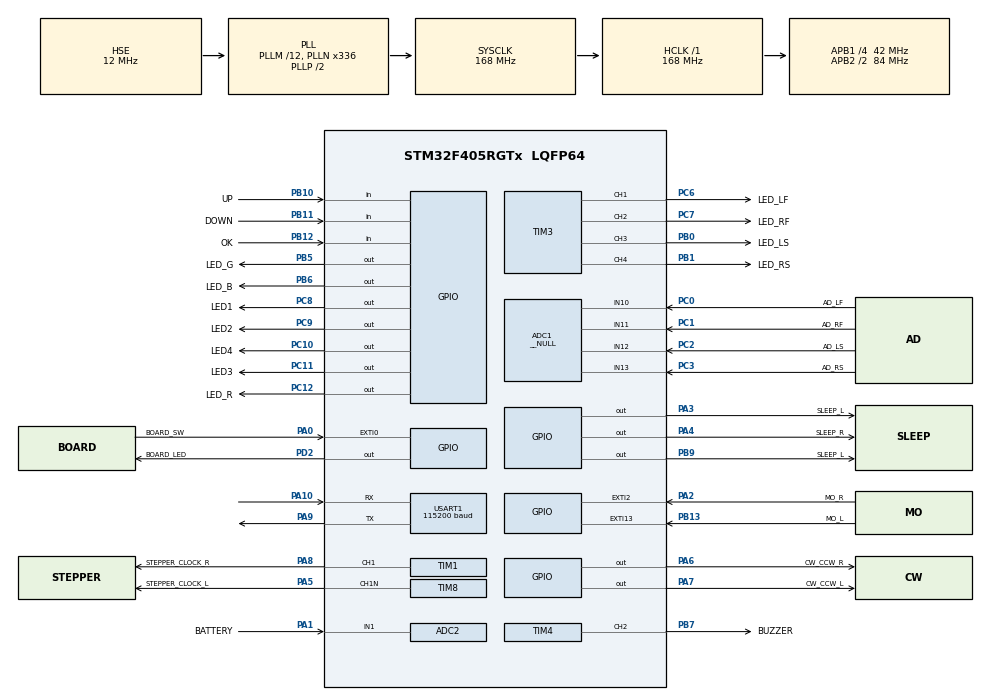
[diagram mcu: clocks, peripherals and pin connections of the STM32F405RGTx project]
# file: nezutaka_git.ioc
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ADC1.Channel-2\#ChannelRegularConversion=ADC_CHANNEL_10
ADC1.Mode=__NULL
ADC1.NbrOfConversionFlag=1
ADC1.Rank-2\#ChannelRegularConversion=1
ADC1.SamplingTime-2\#ChannelRegularConversion=ADC_SAMPLETIME_3CYCLES
ADC1.master=1
ADC2.Channel-0\#ChannelRegularConversion=ADC_CHANNEL_1
ADC2.NbrOfConversionFlag=1
ADC2.Rank-0\#ChannelRegularConversion=1
ADC2.SamplingTime-0\#ChannelRegularConversion=ADC_SAMPLETIME_3CYCLES
FREERTOS.BinarySemaphores01=wait_usSem,Dynamic,NULL;pwm_setSem,Dynamic,NULL;sensor_readSem,Dynamic,NULL;SchengeRSem,Dynamic,NULL;SchengeLSem,Dynamic,NULL;pid_Sem,Dynamic,NULL
FREERTOS.Mutexes01=UART_Mutex,Dynamic,NULL
FREERTOS.Tasks01=defaultTask,28,4096,StartDefaultTask,Default,NULL,Dynamic,NULL,NULL;Sensor_Task,28,512,Sensor,Default,NULL,Dynamic,NULL,NULL;BUZZER_Task,28,256,BUZZER,Default,NULL,Dynamic,NULL,NULL;BATTERY_CHECK,28,256,BatteryCheck,Default,NULL,Dynamic,NULL,NULL;SENSOR_PRINT_TA,28,256,SENSOR_PRINT,Default,NULL,Dynamic,NULL,NULL;MORTOR_SLEEP_CH,28,256,MORTOR_SLEEP_CHECK,Default,NULL,Dynamic,NULL,NULL;PID_Task,28,512,PID,Default,NULL,Dynamic,NULL,NULL
FREERTOS.configENABLE_FPU=1
FREERTOS.configTOTAL_HEAP_SIZE=30720
FREERTOS.configUSE_NEWLIB_REENTRANT=0
Mcu.Family=STM32F4
Mcu.Name=STM32F405RGTx
Mcu.Package=LQFP64
NVIC.EXTI0_IRQn=true\:5\:0\:false\:false\:true\:true\:true\:true
NVIC.EXTI15_10_IRQn=true\:5\:0\:false\:false\:true\:true\:true\:true
NVIC.EXTI2_IRQn=true\:5\:0\:false\:false\:true\:true\:true\:true
NVIC.PriorityGroup=NVIC_PRIORITYGROUP_4
NVIC.TIM1_TRG_COM_TIM11_IRQn=true\:0\:0\:false\:false\:true\:false\:false\:true
NVIC.TIM2_IRQn=true\:5\:0\:false\:false\:true\:true\:true\:true
NVIC.TIM8_BRK_TIM12_IRQn=true\:0\:0\:false\:false\:true\:false\:false\:true
NVIC.TimeBase=TIM1_TRG_COM_TIM11_IRQn
NVIC.TimeBaseIP=TIM11
PA0-WKUP.GPIO_Label=BOARD_SW
PA0-WKUP.Signal=GPXTI0
PA1.GPIO_Label=BATTERY
PA1.Signal=ADCx_IN1
PA10.Mode=Asynchronous
PA10.Signal=USART1_RX
PA11.Signal=USB_OTG_FS_DM
PA12.Signal=USB_OTG_FS_DP
PA13.Mode=Serial_Wire
PA13.Signal=SYS_JTMS-SWDIO
PA14.Mode=Serial_Wire
PA14.Signal=SYS_JTCK-SWCLK
PA15.Signal=SYS_JTDI
PA2.GPIO_Label=MO_R
PA2.GPIO_ModeDefaultEXTI=GPIO_MODE_IT_RISING_FALLING
PA2.Signal=GPXTI2
PA3.GPIO_Label=SLEEP_L
PA3.PinState=GPIO_PIN_SET
PA3.Signal=GPIO_Output
PA4.GPIO_Label=SLEEP_R
PA4.PinState=GPIO_PIN_SET
PA4.Signal=GPIO_Output
PA5.GPIO_Label=STEPPER_CLOCK_L
PA5.Mode=PWM Generation1 CH1N
PA5.Signal=TIM8_CH1N
PA6.GPIO_Label=CW_CCW_R
PA6.Signal=GPIO_Output
PA7.GPIO_Label=CW_CCW_L
PA7.Signal=GPIO_Output
PA8.GPIO_Label=STEPPER_CLOCK_R
PA8.Signal=S_TIM1_CH1
PA9.Mode=Asynchronous
PA9.Signal=USART1_TX
PB0.GPIO_Label=LED_LS
PB0.Signal=S_TIM3_CH3
PB1.GPIO_Label=LED_RS
PB1.Signal=S_TIM3_CH4
PB10.GPIO_Label=UP
PB10.GPIO_PuPd=GPIO_NOPULL
PB10.Signal=GPIO_Input
PB11.GPIO_Label=DOWN
PB11.GPIO_PuPd=GPIO_NOPULL
PB11.Signal=GPIO_Input
PB12.GPIO_Label=OK
PB12.GPIO_PuPd=GPIO_NOPULL
PB12.Signal=GPIO_Input
PB13.GPIO_Label=MO_L
PB13.GPIO_ModeDefaultEXTI=GPIO_MODE_IT_RISING_FALLING
PB13.Signal=GPXTI13
PB3.Signal=SYS_JTDO-SWO
PB4.Signal=SYS_JTRST
PB5.GPIO_Label=LED_G
PB5.PinState=GPIO_PIN_SET
PB5.Signal=GPIO_Output
PB6.GPIO_Label=LED_B
PB6.PinState=GPIO_PIN_SET
PB6.Signal=GPIO_Output
PB7.GPIO_Label=BUZZER
PB7.Signal=S_TIM4_CH2
PB9.GPIO_Label=SLEEP_L
PB9.Signal=GPIO_Output
PC0.GPIO_Label=AD_LF
PC0.Signal=ADCx_IN10
PC1.GPIO_Label=AD_RF
PC1.Signal=ADCx_IN11
PC10.GPIO_Label=LED4
PC10.PinState=GPIO_PIN_SET
PC10.Signal=GPIO_Output
PC11.GPIO_Label=LED3
PC11.PinState=GPIO_PIN_SET
PC11.Signal=GPIO_Output
PC12.GPIO_Label=LED_R
PC12.PinState=GPIO_PIN_SET
PC12.Signal=GPIO_Output
PC14-OSC32_IN.Mode=LSE-External-Oscillator
PC14-OSC32_IN.Signal=RCC_OSC32_IN
PC15-OSC32_OUT.Mode=LSE-External-Oscillator
PC15-OSC32_OUT.Signal=RCC_OSC32_OUT
PC2.GPIO_Label=AD_LS
PC2.Signal=ADCx_IN12
PC3.GPIO_Label=AD_RS
PC3.Signal=ADCx_IN13
PC6.GPIO_Label=LED_LF
PC6.Signal=S_TIM3_CH1
PC7.GPIO_Label=LED_RF
PC7.Signal=S_TIM3_CH2
PC8.GPIO_Label=LED1
PC8.PinState=GPIO_PIN_SET
PC8.Signal=GPIO_Output
PC9.GPIO_Label=LED2
PC9.PinState=GPIO_PIN_SET
PC9.Signal=GPIO_Output
PD2.GPIO_Label=BOARD_LED
PD2.PinState=GPIO_PIN_SET
PD2.Signal=GPIO_Output
PH0-OSC_IN.Mode=HSE-External-Oscillator
PH0-OSC_IN.Signal=RCC_OSC_IN
PH1-OSC_OUT.Mode=HSE-External-Oscillator
PH1-OSC_OUT.Signal=RCC_OSC_OUT
ProjectManager.HeapSize=0x200
ProjectManager.StackSize=0x400
ProjectManager.TargetToolchain=STM32CubeIDE
RCC.48MHZClocksFreq_Value=84000000
RCC.AHBFreq_Value=168000000
RCC.APB1CLKDivider=RCC_HCLK_DIV4
RCC.APB1Freq_Value=42000000
RCC.APB1TimFreq_Value=84000000
RCC.APB2CLKDivider=RCC_HCLK_DIV2
RCC.APB2Freq_Value=84000000
RCC.APB2TimFreq_Value=168000000
RCC.CortexFreq_Value=168000000
RCC.HCLKFreq_Value=168000000
RCC.HSE_VALUE=12000000
RCC.HSI_VALUE=16000000
RCC.PLLM=12
RCC.PLLN=336
RCC.PLLSourceVirtual=RCC_PLLSOURCE_HSE
RCC.SYSCLKFreq_VALUE=168000000
RCC.SYSCLKSource=RCC_SYSCLKSOURCE_PLLCLK
RCC.VCOOutputFreq_Value=336000000
SH.ADCx_IN1.0=ADC2_IN1,IN1
SH.ADCx_IN10.0=ADC1_IN10,IN10
SH.ADCx_IN11.0=ADC1_IN11,IN11
SH.ADCx_IN12.0=ADC1_IN12,IN12
SH.ADCx_IN13.0=ADC1_IN13,IN13
SH.S_TIM1_CH1.0=TIM1_CH1,PWM Generation1 CH1
SH.S_TIM3_CH1.0=TIM3_CH1,PWM Generation1 CH1
SH.S_TIM3_CH2.0=TIM3_CH2,PWM Generation2 CH2
SH.S_TIM3_CH3.0=TIM3_CH3,PWM Generation3 CH3
SH.S_TIM3_CH4.0=TIM3_CH4,PWM Generation4 CH4
SH.S_TIM4_CH2.0=TIM4_CH2,PWM Generation2 CH2
TIM1.Channel-PWM\ Generation1\ CH1=TIM_CHANNEL_1
TIM2.Period=1
TIM2.Prescaler=41
TIM3.Channel-PWM\ Generation1\ CH1=TIM_CHANNEL_1
TIM3.Channel-PWM\ Generation2\ CH2=TIM_CHANNEL_2
TIM3.Channel-PWM\ Generation3\ CH3=TIM_CHANNEL_3
TIM3.Channel-PWM\ Generation4\ CH4=TIM_CHANNEL_4
TIM4.Channel-PWM\ Generation2\ CH2=TIM_CHANNEL_2
TIM8.Channel-PWM\ Generation1\ CH1N=TIM_CHANNEL_1
USART1.BaudRate=115200
USART1.VirtualMode=VM_ASYNC
VP_FREERTOS_VS_CMSIS_V2.Mode=CMSIS_V2
VP_SYS_VS_tim11.Mode=TIM11
VP_TIM2_VS_ClockSourceINT.Mode=Internal
board=custom

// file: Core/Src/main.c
/* USER CODE BEGIN Header */
/**
 ******************************************************************************
 * @file           : main.c
 * @brief          : Main program body
 ******************************************************************************
 * @attention
 *
 * <h2><center>&copy; Copyright (c) 2020 STMicroelectronics.
 * All rights reserved.</center></h2>
 *
 * This software component is licensed by ST under BSD 3-Clause license,
 * the "License"; You may not use this file except in compliance with the
 * License. You may obtain a copy of the License at:
 *                        opensource.org/licenses/BSD-3-Clause
 *
 ******************************************************************************
 */
/* USER CODE END Header */

#include "main.h"
#include "cmsis_os.h"

/* USER CODE BEGIN Includes */
#include "sensor.h"
#include "timer.h"
#include "buzzer.h"
#include "motor.h"
#include "UI.h"
#include "nezutaka.h"
/* USER CODE END Includes */

ADC_HandleTypeDef hadc1;
ADC_HandleTypeDef hadc2;

TIM_HandleTypeDef htim1;
TIM_HandleTypeDef htim2;
TIM_HandleTypeDef htim3;
TIM_HandleTypeDef htim4;
TIM_HandleTypeDef htim8;

UART_HandleTypeDef huart1;

/* Definitions for defaultTask */
osThreadId_t defaultTaskHandle;
const osThreadAttr_t defaultTask_attributes = {
  .name = "defaultTask",
  .priority = (osPriority_t) osPriorityNormal4,
  .stack_size = 4096 * 4
};
/* Definitions for Sensor_Task */
osThreadId_t Sensor_TaskHandle;
const osThreadAttr_t Sensor_Task_attributes = {
  .name = "Sensor_Task",
  .priority = (osPriority_t) osPriorityNormal4,
  .stack_size = 512 * 4
};
/* Definitions for BUZZER_Task */
osThreadId_t BUZZER_TaskHandle;
const osThreadAttr_t BUZZER_Task_attributes = {
  .name = "BUZZER_Task",
  .priority = (osPriority_t) osPriorityNormal4,
  .stack_size = 256 * 4
};
/* Definitions for BATTERY_CHECK */
osThreadId_t BATTERY_CHECKHandle;
const osThreadAttr_t BATTERY_CHECK_attributes = {
  .name = "BATTERY_CHECK",
  .priority = (osPriority_t) osPriorityNormal4,
  .stack_size = 256 * 4
};
/* Definitions for SENSOR_PRINT_TA */
osThreadId_t SENSOR_PRINT_TAHandle;
const osThreadAttr_t SENSOR_PRINT_TA_attributes = {
  .name = "SENSOR_PRINT_TA",
  .priority = (osPriority_t) osPriorityNormal4,
  .stack_size = 256 * 4
};
/* Definitions for MORTOR_SLEEP_CH */
osThreadId_t MORTOR_SLEEP_CHHandle;
const osThreadAttr_t MORTOR_SLEEP_CH_attributes = {
  .name = "MORTOR_SLEEP_CH",
  .priority = (osPriority_t) osPriorityNormal4,
  .stack_size = 256 * 4
};
/* Definitions for PID_Task */
osThreadId_t PID_TaskHandle;
const osThreadAttr_t PID_Task_attributes = {
  .name = "PID_Task",
  .priority = (osPriority_t) osPriorityNormal4,
  .stack_size = 512 * 4
};
/* Definitions for UART_Mutex */
osMutexId_t UART_MutexHandle;
const osMutexAttr_t UART_Mutex_attributes = {
  .name = "UART_Mutex"
};
/* Definitions for wait_usSem */
osSemaphoreId_t wait_usSemHandle;
const osSemaphoreAttr_t wait_usSem_attributes = {
  .name = "wait_usSem"
};
/* Definitions for pwm_setSem */
osSemaphoreId_t pwm_setSemHandle;
const osSemaphoreAttr_t pwm_setSem_attributes = {
  .name = "pwm_setSem"
};
/* Definitions for sensor_readSem */
osSemaphoreId_t sensor_readSemHandle;
const osSemaphoreAttr_t sensor_readSem_attributes = {
  .name = "sensor_readSem"
};
/* Definitions for SchengeRSem */
osSemaphoreId_t SchengeRSemHandle;
const osSemaphoreAttr_t SchengeRSem_attributes = {
  .name = "SchengeRSem"
};
/* Definitions for SchengeLSem */
osSemaphoreId_t SchengeLSemHandle;
const osSemaphoreAttr_t SchengeLSem_attributes = {
  .name = "SchengeLSem"
};
/* Definitions for pid_Sem */
osSemaphoreId_t pid_SemHandle;
const osSemaphoreAttr_t pid_Sem_attributes = {
  .name = "pid_Sem"
};

void SystemClock_Config(void);
static void MX_GPIO_Init(void);
static void MX_ADC1_Init(void);
static void MX_TIM1_Init(void);
static void MX_TIM3_Init(void);
static void MX_TIM4_Init(void);
static void MX_TIM8_Init(void);
static void MX_USART1_UART_Init(void);
static void MX_TIM2_Init(void);
static void MX_ADC2_Init(void);
void StartDefaultTask(void *argument);
void Sensor(void *argument);
void BUZZER(void *argument);
void BatteryCheck(void *argument);
void SENSOR_PRINT(void *argument);
void MORTOR_SLEEP_CHECK(void *argument);
void PID(void *argument);

int main(void)
{

  /* MCU Configuration--------------------------------------------------------*/

  /* Reset of all peripherals, Initializes the Flash interface and the Systick. */
  HAL_Init();

  /* Configure the system clock */
  SystemClock_Config();

  /* Initialize all configured peripherals */
  MX_GPIO_Init();
  MX_ADC1_Init();
  MX_TIM1_Init();
  MX_TIM3_Init();
  MX_TIM4_Init();
  MX_TIM8_Init();
  MX_USART1_UART_Init();
  MX_TIM2_Init();
  MX_ADC2_Init();
  /* USER CODE BEGIN 2 */
	setbuf(stdout, NULL); //buff不使用
//HAL_TIM_Base_Stop_IT(&htim2);
//	printf("hello!\n");
  /* USER CODE END 2 */

  /* Init scheduler */
  osKernelInitialize();
  /* Create the mutex(es) */
  /* creation of UART_Mutex */
  UART_MutexHandle = osMutexNew(&UART_Mutex_attributes);

  /* Create the semaphores(s) */
  /* creation of wait_usSem */
  wait_usSemHandle = osSemaphoreNew(1, 1, &wait_usSem_attributes);

  /* creation of pwm_setSem */
  pwm_setSemHandle = osSemaphoreNew(1, 1, &pwm_setSem_attributes);

  /* creation of sensor_readSem */
  sensor_readSemHandle = osSemaphoreNew(1, 1, &sensor_readSem_attributes);

  /* creation of SchengeRSem */
  SchengeRSemHandle = osSemaphoreNew(1, 1, &SchengeRSem_attributes);

  /* creation of SchengeLSem */
  SchengeLSemHandle = osSemaphoreNew(1, 1, &SchengeLSem_attributes);

  /* creation of pid_Sem */
  pid_SemHandle = osSemaphoreNew(1, 1, &pid_Sem_attributes);

  /* Create the thread(s) */
  /* creation of defaultTask */
  defaultTaskHandle = osThreadNew(StartDefaultTask, NULL, &defaultTask_attributes);

  /* creation of Sensor_Task */
  Sensor_TaskHandle = osThreadNew(Sensor, NULL, &Sensor_Task_attributes);

  /* creation of BUZZER_Task */
  BUZZER_TaskHandle = osThreadNew(BUZZER, NULL, &BUZZER_Task_attributes);

  /* creation of BATTERY_CHECK */
  BATTERY_CHECKHandle = osThreadNew(BatteryCheck, NULL, &BATTERY_CHECK_attributes);

  /* creation of SENSOR_PRINT_TA */
  SENSOR_PRINT_TAHandle = osThreadNew(SENSOR_PRINT, NULL, &SENSOR_PRINT_TA_attributes);

  /* creation of MORTOR_SLEEP_CH */
  MORTOR_SLEEP_CHHandle = osThreadNew(MORTOR_SLEEP_CHECK, NULL, &MORTOR_SLEEP_CH_attributes);

  /* creation of PID_Task */
  PID_TaskHandle = osThreadNew(PID, NULL, &PID_Task_attributes);

  /* Start scheduler */
  osKernelStart();

  /* We should never get here as control is now taken by the scheduler */
  /* Infinite loop */
	while (1) {

	}
}

void SystemClock_Config(void)
{
  RCC_OscInitTypeDef RCC_OscInitStruct = {0};
  RCC_ClkInitTypeDef RCC_ClkInitStruct = {0};

  /** Configure the main internal regulator output voltage
  */
  __HAL_RCC_PWR_CLK_ENABLE();
  __HAL_PWR_VOLTAGESCALING_CONFIG(PWR_REGULATOR_VOLTAGE_SCALE1);
  /** Initializes the CPU, AHB and APB busses clocks
  */
  RCC_OscInitStruct.OscillatorType = RCC_OSCILLATORTYPE_HSE;
  RCC_OscInitStruct.HSEState = RCC_HSE_ON;
  RCC_OscInitStruct.PLL.PLLState = RCC_PLL_ON;
  RCC_OscInitStruct.PLL.PLLSource = RCC_PLLSOURCE_HSE;
  RCC_OscInitStruct.PLL.PLLM = 12;
  RCC_OscInitStruct.PLL.PLLN = 336;
  RCC_OscInitStruct.PLL.PLLP = RCC_PLLP_DIV2;
  RCC_OscInitStruct.PLL.PLLQ = 4;
  if (HAL_RCC_OscConfig(&RCC_OscInitStruct) != HAL_OK)
  {
    Error_Handler();
  }
  /** Initializes the CPU, AHB and APB busses clocks
  */
  RCC_ClkInitStruct.ClockType = RCC_CLOCKTYPE_HCLK|RCC_CLOCKTYPE_SYSCLK
                              |RCC_CLOCKTYPE_PCLK1|RCC_CLOCKTYPE_PCLK2;
  RCC_ClkInitStruct.SYSCLKSource = RCC_SYSCLKSOURCE_PLLCLK;
  RCC_ClkInitStruct.AHBCLKDivider = RCC_SYSCLK_DIV1;
  RCC_ClkInitStruct.APB1CLKDivider = RCC_HCLK_DIV4;
  RCC_ClkInitStruct.APB2CLKDivider = RCC_HCLK_DIV2;

  if (HAL_RCC_ClockConfig(&RCC_ClkInitStruct, FLASH_LATENCY_5) != HAL_OK)
  {
    Error_Handler();
  }
}

static void MX_ADC1_Init(void)
{

  ADC_ChannelConfTypeDef sConfig = {0};

  /** Configure the global features of the ADC (Clock, Resolution, Data Alignment and number of conversion)
  */
  hadc1.Instance = ADC1;
  hadc1.Init.ClockPrescaler = ADC_CLOCK_SYNC_PCLK_DIV4;
  hadc1.Init.Resolution = ADC_RESOLUTION_12B;
  hadc1.Init.ScanConvMode = DISABLE;
  hadc1.Init.ContinuousConvMode = DISABLE;
  hadc1.Init.DiscontinuousConvMode = DISABLE;
  hadc1.Init.ExternalTrigConvEdge = ADC_EXTERNALTRIGCONVEDGE_NONE;
  hadc1.Init.ExternalTrigConv = ADC_SOFTWARE_START;
  hadc1.Init.DataAlign = ADC_DATAALIGN_RIGHT;
  hadc1.Init.NbrOfConversion = 1;
  hadc1.Init.DMAContinuousRequests = DISABLE;
  hadc1.Init.EOCSelection = ADC_EOC_SINGLE_CONV;
  if (HAL_ADC_Init(&hadc1) != HAL_OK)
  {
    Error_Handler();
  }
  /** Configure for the selected ADC regular channel its corresponding rank in the sequencer and its sample time.
  */
  sConfig.Channel = ADC_CHANNEL_10;
  sConfig.Rank = 1;
  sConfig.SamplingTime = ADC_SAMPLETIME_3CYCLES;
  if (HAL_ADC_ConfigChannel(&hadc1, &sConfig) != HAL_OK)
  {
    Error_Handler();
  }

}

static void MX_ADC2_Init(void)
{

  ADC_ChannelConfTypeDef sConfig = {0};

  /** Configure the global features of the ADC (Clock, Resolution, Data Alignment and number of conversion)
  */
  hadc2.Instance = ADC2;
  hadc2.Init.ClockPrescaler = ADC_CLOCK_SYNC_PCLK_DIV4;
  hadc2.Init.Resolution = ADC_RESOLUTION_12B;
  hadc2.Init.ScanConvMode = DISABLE;
  hadc2.Init.ContinuousConvMode = DISABLE;
  hadc2.Init.DiscontinuousConvMode = DISABLE;
  hadc2.Init.ExternalTrigConvEdge = ADC_EXTERNALTRIGCONVEDGE_NONE;
  hadc2.Init.ExternalTrigConv = ADC_SOFTWARE_START;
  hadc2.Init.DataAlign = ADC_DATAALIGN_RIGHT;
  hadc2.Init.NbrOfConversion = 1;
  hadc2.Init.DMAContinuousRequests = DISABLE;
  hadc2.Init.EOCSelection = ADC_EOC_SINGLE_CONV;
  if (HAL_ADC_Init(&hadc2) != HAL_OK)
  {
    Error_Handler();
  }
  /** Configure for the selected ADC regular channel its corresponding rank in the sequencer and its sample time.
  */
  sConfig.Channel = ADC_CHANNEL_1;
  sConfig.Rank = 1;
  sConfig.SamplingTime = ADC_SAMPLETIME_3CYCLES;
  if (HAL_ADC_ConfigChannel(&hadc2, &sConfig) != HAL_OK)
  {
    Error_Handler();
  }

}

static void MX_TIM1_Init(void)
{

  TIM_MasterConfigTypeDef sMasterConfig = {0};
  TIM_OC_InitTypeDef sConfigOC = {0};
  TIM_BreakDeadTimeConfigTypeDef sBreakDeadTimeConfig = {0};

  htim1.Instance = TIM1;
  htim1.Init.Prescaler = 0;
  htim1.Init.CounterMode = TIM_COUNTERMODE_UP;
  htim1.Init.Period = 0;
  htim1.Init.ClockDivision = TIM_CLOCKDIVISION_DIV1;
  htim1.Init.RepetitionCounter = 0;
  htim1.Init.AutoReloadPreload = TIM_AUTORELOAD_PRELOAD_DISABLE;
  if (HAL_TIM_PWM_Init(&htim1) != HAL_OK)
  {
    Error_Handler();
  }
  sMasterConfig.MasterOutputTrigger = TIM_TRGO_RESET;
  sMasterConfig.MasterSlaveMode = TIM_MASTERSLAVEMODE_DISABLE;
  if (HAL_TIMEx_MasterConfigSynchronization(&htim1, &sMasterConfig) != HAL_OK)
  {
    Error_Handler();
  }
  sConfigOC.OCMode = TIM_OCMODE_PWM1;
  sConfigOC.Pulse = 0;
  sConfigOC.OCPolarity = TIM_OCPOLARITY_HIGH;
  sConfigOC.OCNPolarity = TIM_OCNPOLARITY_HIGH;
  sConfigOC.OCFastMode = TIM_OCFAST_DISABLE;
  sConfigOC.OCIdleState = TIM_OCIDLESTATE_RESET;
  sConfigOC.OCNIdleState = TIM_OCNIDLESTATE_RESET;
  if (HAL_TIM_PWM_ConfigChannel(&htim1, &sConfigOC, TIM_CHANNEL_1) != HAL_OK)
  {
    Error_Handler();
  }
  sBreakDeadTimeConfig.OffStateRunMode = TIM_OSSR_DISABLE;
  sBreakDeadTimeConfig.OffStateIDLEMode = TIM_OSSI_DISABLE;
  sBreakDeadTimeConfig.LockLevel = TIM_LOCKLEVEL_OFF;
  sBreakDeadTimeConfig.DeadTime = 0;
  sBreakDeadTimeConfig.BreakState = TIM_BREAK_DISABLE;
  sBreakDeadTimeConfig.BreakPolarity = TIM_BREAKPOLARITY_HIGH;
  sBreakDeadTimeConfig.AutomaticOutput = TIM_AUTOMATICOUTPUT_DISABLE;
  if (HAL_TIMEx_ConfigBreakDeadTime(&htim1, &sBreakDeadTimeConfig) != HAL_OK)
  {
    Error_Handler();
  }
  HAL_TIM_MspPostInit(&htim1);

}

static void MX_TIM2_Init(void)
{

  TIM_ClockConfigTypeDef sClockSourceConfig = {0};
  TIM_MasterConfigTypeDef sMasterConfig = {0};

  htim2.Instance = TIM2;
  htim2.Init.Prescaler = 41;
  htim2.Init.CounterMode = TIM_COUNTERMODE_UP;
  htim2.Init.Period = 1;
  htim2.Init.ClockDivision = TIM_CLOCKDIVISION_DIV1;
  htim2.Init.AutoReloadPreload = TIM_AUTORELOAD_PRELOAD_DISABLE;
  if (HAL_TIM_Base_Init(&htim2) != HAL_OK)
  {
    Error_Handler();
  }
  sClockSourceConfig.ClockSource = TIM_CLOCKSOURCE_INTERNAL;
  if (HAL_TIM_ConfigClockSource(&htim2, &sClockSourceConfig) != HAL_OK)
  {
    Error_Handler();
  }
  sMasterConfig.MasterOutputTrigger = TIM_TRGO_RESET;
  sMasterConfig.MasterSlaveMode = TIM_MASTERSLAVEMODE_DISABLE;
  if (HAL_TIMEx_MasterConfigSynchronization(&htim2, &sMasterConfig) != HAL_OK)
  {
    Error_Handler();
  }

}

static void MX_TIM3_Init(void)
{

  TIM_MasterConfigTypeDef sMasterConfig = {0};
  TIM_OC_InitTypeDef sConfigOC = {0};

  htim3.Instance = TIM3;
  htim3.Init.Prescaler = 0;
  htim3.Init.CounterMode = TIM_COUNTERMODE_UP;
  htim3.Init.Period = 0;
  htim3.Init.ClockDivision = TIM_CLOCKDIVISION_DIV1;
  htim3.Init.AutoReloadPreload = TIM_AUTORELOAD_PRELOAD_DISABLE;
  if (HAL_TIM_PWM_Init(&htim3) != HAL_OK)
  {
    Error_Handler();
  }
  sMasterConfig.MasterOutputTrigger = TIM_TRGO_RESET;
  sMasterConfig.MasterSlaveMode = TIM_MASTERSLAVEMODE_DISABLE;
  if (HAL_TIMEx_MasterConfigSynchronization(&htim3, &sMasterConfig) != HAL_OK)
  {
    Error_Handler();
  }
  sConfigOC.OCMode = TIM_OCMODE_PWM1;
  sConfigOC.Pulse = 0;
  sConfigOC.OCPolarity = TIM_OCPOLARITY_HIGH;
  sConfigOC.OCFastMode = TIM_OCFAST_DISABLE;
  if (HAL_TIM_PWM_ConfigChannel(&htim3, &sConfigOC, TIM_CHANNEL_1) != HAL_OK)
  {
    Error_Handler();
  }
  if (HAL_TIM_PWM_ConfigChannel(&htim3, &sConfigOC, TIM_CHANNEL_2) != HAL_OK)
  {
    Error_Handler();
  }
  if (HAL_TIM_PWM_ConfigChannel(&htim3, &sConfigOC, TIM_CHANNEL_3) != HAL_OK)
  {
    Error_Handler();
  }
  if (HAL_TIM_PWM_ConfigChannel(&htim3, &sConfigOC, TIM_CHANNEL_4) != HAL_OK)
  {
    Error_Handler();
  }
  HAL_TIM_MspPostInit(&htim3);

}

static void MX_TIM4_Init(void)
{

  TIM_MasterConfigTypeDef sMasterConfig = {0};
  TIM_OC_InitTypeDef sConfigOC = {0};

  htim4.Instance = TIM4;
  htim4.Init.Prescaler = 0;
  htim4.Init.CounterMode = TIM_COUNTERMODE_UP;
  htim4.Init.Period = 0;
  htim4.Init.ClockDivision = TIM_CLOCKDIVISION_DIV1;
  htim4.Init.AutoReloadPreload = TIM_AUTORELOAD_PRELOAD_DISABLE;
  if (HAL_TIM_PWM_Init(&htim4) != HAL_OK)
  {
    Error_Handler();
  }
  sMasterConfig.MasterOutputTrigger = TIM_TRGO_RESET;
  sMasterConfig.MasterSlaveMode = TIM_MASTERSLAVEMODE_DISABLE;
  if (HAL_TIMEx_MasterConfigSynchronization(&htim4, &sMasterConfig) != HAL_OK)
  {
    Error_Handler();
  }
  sConfigOC.OCMode = TIM_OCMODE_PWM1;
  sConfigOC.Pulse = 0;
  sConfigOC.OCPolarity = TIM_OCPOLARITY_HIGH;
  sConfigOC.OCFastMode = TIM_OCFAST_DISABLE;
  if (HAL_TIM_PWM_ConfigChannel(&htim4, &sConfigOC, TIM_CHANNEL_2) != HAL_OK)
  {
    Error_Handler();
  }
  HAL_TIM_MspPostInit(&htim4);

}

static void MX_TIM8_Init(void)
{

  TIM_MasterConfigTypeDef sMasterConfig = {0};
  TIM_OC_InitTypeDef sConfigOC = {0};
  TIM_BreakDeadTimeConfigTypeDef sBreakDeadTimeConfig = {0};

  htim8.Instance = TIM8;
  htim8.Init.Prescaler = 0;
  htim8.Init.CounterMode = TIM_COUNTERMODE_UP;
  htim8.Init.Period = 0;
  htim8.Init.ClockDivision = TIM_CLOCKDIVISION_DIV1;
  htim8.Init.RepetitionCounter = 0;
  htim8.Init.AutoReloadPreload = TIM_AUTORELOAD_PRELOAD_DISABLE;
  if (HAL_TIM_PWM_Init(&htim8) != HAL_OK)
  {
    Error_Handler();
  }
  sMasterConfig.MasterOutputTrigger = TIM_TRGO_RESET;
  sMasterConfig.MasterSlaveMode = TIM_MASTERSLAVEMODE_DISABLE;
  if (HAL_TIMEx_MasterConfigSynchronization(&htim8, &sMasterConfig) != HAL_OK)
  {
    Error_Handler();
  }
  sConfigOC.OCMode = TIM_OCMODE_PWM1;
  sConfigOC.Pulse = 0;
  sConfigOC.OCPolarity = TIM_OCPOLARITY_HIGH;
  sConfigOC.OCNPolarity = TIM_OCNPOLARITY_HIGH;
  sConfigOC.OCFastMode = TIM_OCFAST_DISABLE;
  sConfigOC.OCIdleState = TIM_OCIDLESTATE_RESET;
  sConfigOC.OCNIdleState = TIM_OCNIDLESTATE_RESET;
  if (HAL_TIM_PWM_ConfigChannel(&htim8, &sConfigOC, TIM_CHANNEL_1) != HAL_OK)
  {
    Error_Handler();
  }
  sBreakDeadTimeConfig.OffStateRunMode = TIM_OSSR_DISABLE;
  sBreakDeadTimeConfig.OffStateIDLEMode = TIM_OSSI_DISABLE;
  sBreakDeadTimeConfig.LockLevel = TIM_LOCKLEVEL_OFF;
  sBreakDeadTimeConfig.DeadTime = 0;
  sBreakDeadTimeConfig.BreakState = TIM_BREAK_DISABLE;
  sBreakDeadTimeConfig.BreakPolarity = TIM_BREAKPOLARITY_HIGH;
  sBreakDeadTimeConfig.AutomaticOutput = TIM_AUTOMATICOUTPUT_DISABLE;
  if (HAL_TIMEx_ConfigBreakDeadTime(&htim8, &sBreakDeadTimeConfig) != HAL_OK)
  {
    Error_Handler();
  }
  HAL_TIM_MspPostInit(&htim8);

}

static void MX_USART1_UART_Init(void)
{

  huart1.Instance = USART1;
  huart1.Init.BaudRate = 115200;
  huart1.Init.WordLength = UART_WORDLENGTH_8B;
  huart1.Init.StopBits = UART_STOPBITS_1;
  huart1.Init.Parity = UART_PARITY_NONE;
  huart1.Init.Mode = UART_MODE_TX_RX;
  huart1.Init.HwFlowCtl = UART_HWCONTROL_NONE;
  huart1.Init.OverSampling = UART_OVERSAMPLING_16;
  if (HAL_UART_Init(&huart1) != HAL_OK)
  {
    Error_Handler();
  }

}

static void MX_GPIO_Init(void)
{
  GPIO_InitTypeDef GPIO_InitStruct = {0};

  /* GPIO Ports Clock Enable */
  __HAL_RCC_GPIOC_CLK_ENABLE();
  __HAL_RCC_GPIOH_CLK_ENABLE();
  __HAL_RCC_GPIOA_CLK_ENABLE();
  __HAL_RCC_GPIOB_CLK_ENABLE();
  __HAL_RCC_GPIOD_CLK_ENABLE();

  /*Configure GPIO pin Output Level */
  HAL_GPIO_WritePin(GPIOA, SLEEP_L_Pin|SLEEP_R_Pin, GPIO_PIN_SET);

  /*Configure GPIO pin Output Level */
  HAL_GPIO_WritePin(GPIOA, CW_CCW_R_Pin|CW_CCW_L_Pin, GPIO_PIN_RESET);

  /*Configure GPIO pin Output Level */
  HAL_GPIO_WritePin(GPIOC, LED1_Pin|LED2_Pin|LED4_Pin|LED3_Pin
                          |LED_R_Pin, GPIO_PIN_SET);

  /*Configure GPIO pin Output Level */
  HAL_GPIO_WritePin(BOARD_LED_GPIO_Port, BOARD_LED_Pin, GPIO_PIN_SET);

  /*Configure GPIO pin Output Level */
  HAL_GPIO_WritePin(GPIOB, LED_G_Pin|LED_B_Pin, GPIO_PIN_SET);

  /*Configure GPIO pin Output Level */
  HAL_GPIO_WritePin(SLEEP_LB9_GPIO_Port, SLEEP_LB9_Pin, GPIO_PIN_RESET);

  /*Configure GPIO pin : BOARD_SW_Pin */
  GPIO_InitStruct.Pin = BOARD_SW_Pin;
  GPIO_InitStruct.Mode = GPIO_MODE_IT_RISING;
  GPIO_InitStruct.Pull = GPIO_NOPULL;
  HAL_GPIO_Init(BOARD_SW_GPIO_Port, &GPIO_InitStruct);

  /*Configure GPIO pin : MO_R_Pin */
  GPIO_InitStruct.Pin = MO_R_Pin;
  GPIO_InitStruct.Mode = GPIO_MODE_IT_RISING_FALLING;
  GPIO_InitStruct.Pull = GPIO_NOPULL;
  HAL_GPIO_Init(MO_R_GPIO_Port, &GPIO_InitStruct);

  /*Configure GPIO pins : SLEEP_L_Pin SLEEP_R_Pin CW_CCW_R_Pin CW_CCW_L_Pin */
  GPIO_InitStruct.Pin = SLEEP_L_Pin|SLEEP_R_Pin|CW_CCW_R_Pin|CW_CCW_L_Pin;
  GPIO_InitStruct.Mode = GPIO_MODE_OUTPUT_PP;
  GPIO_InitStruct.Pull = GPIO_NOPULL;
  GPIO_InitStruct.Speed = GPIO_SPEED_FREQ_LOW;
  HAL_GPIO_Init(GPIOA, &GPIO_InitStruct);

  /*Configure GPIO pins : UP_Pin DOWN_Pin OK_Pin */
  GPIO_InitStruct.Pin = UP_Pin|DOWN_Pin|OK_Pin;
  GPIO_InitStruct.Mode = GPIO_MODE_INPUT;
  GPIO_InitStruct.Pull = GPIO_NOPULL;
  HAL_GPIO_Init(GPIOB, &GPIO_InitStruct);

  /*Configure GPIO pin : MO_L_Pin */
  GPIO_InitStruct.Pin = MO_L_Pin;
  GPIO_InitStruct.Mode = GPIO_MODE_IT_RISING_FALLING;
  GPIO_InitStruct.Pull = GPIO_NOPULL;
  HAL_GPIO_Init(MO_L_GPIO_Port, &GPIO_InitStruct);

  /*Configure GPIO pins : LED1_Pin LED2_Pin LED4_Pin LED3_Pin
                           LED_R_Pin */
  GPIO_InitStruct.Pin = LED1_Pin|LED2_Pin|LED4_Pin|LED3_Pin
                          |LED_R_Pin;
  GPIO_InitStruct.Mode = GPIO_MODE_OUTPUT_PP;
  GPIO_InitStruct.Pull = GPIO_NOPULL;
  GPIO_InitStruct.Speed = GPIO_SPEED_FREQ_LOW;
  HAL_GPIO_Init(GPIOC, &GPIO_InitStruct);

  /*Configure GPIO pins : PA11 PA12 */
  GPIO_InitStruct.Pin = GPIO_PIN_11|GPIO_PIN_12;
  GPIO_InitStruct.Mode = GPIO_MODE_AF_PP;
  GPIO_InitStruct.Pull = GPIO_NOPULL;
  GPIO_InitStruct.Speed = GPIO_SPEED_FREQ_VERY_HIGH;
  GPIO_InitStruct.Alternate = GPIO_AF10_OTG_FS;
  HAL_GPIO_Init(GPIOA, &GPIO_InitStruct);

  /*Configure GPIO pin : BOARD_LED_Pin */
  GPIO_InitStruct.Pin = BOARD_LED_Pin;
  GPIO_InitStruct.Mode = GPIO_MODE_OUTPUT_PP;
  GPIO_InitStruct.Pull = GPIO_NOPULL;
  GPIO_InitStruct.Speed = GPIO_SPEED_FREQ_LOW;
  HAL_GPIO_Init(BOARD_LED_GPIO_Port, &GPIO_InitStruct);

  /*Configure GPIO pins : LED_G_Pin LED_B_Pin SLEEP_LB9_Pin */
  GPIO_InitStruct.Pin = LED_G_Pin|LED_B_Pin|SLEEP_LB9_Pin;
  GPIO_InitStruct.Mode = GPIO_MODE_OUTPUT_PP;
  GPIO_InitStruct.Pull = GPIO_NOPULL;
  GPIO_InitStruct.Speed = GPIO_SPEED_FREQ_LOW;
  HAL_GPIO_Init(GPIOB, &GPIO_InitStruct);

  /* EXTI interrupt init*/
  HAL_NVIC_SetPriority(EXTI0_IRQn, 5, 0);
  HAL_NVIC_EnableIRQ(EXTI0_IRQn);

  HAL_NVIC_SetPriority(EXTI2_IRQn, 5, 0);
  HAL_NVIC_EnableIRQ(EXTI2_IRQn);

  HAL_NVIC_SetPriority(EXTI15_10_IRQn, 5, 0);
  HAL_NVIC_EnableIRQ(EXTI15_10_IRQn);

}

void StartDefaultTask(void *argument)
{
  /* USER CODE BEGIN 5 */
	osSemaphoreAcquire(wait_usSemHandle, 0);
	osSemaphoreAcquire(SchengeLSemHandle, 0);
	osSemaphoreAcquire(SchengeRSemHandle, 0);
	portTASK_USES_FLOATING_POINT();
	Delay_ms(10);

	/* Infinite loop */
	for (;;) {

		nezutaka();
	}
  /* USER CODE END 5 */
}

void Error_Handler(void)
{
}

/************************ (C) COPYRIGHT STMicroelectronics *****END OF FILE****/
